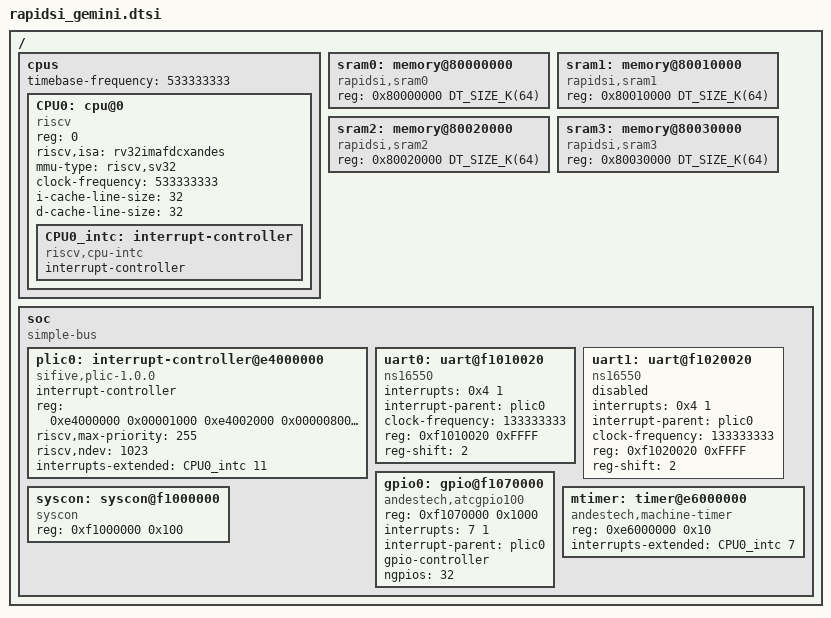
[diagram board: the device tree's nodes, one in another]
/*
 * Copyright (c) 2022 Rapid Silicon
 *
 * SPDX-License-Identifier: Apache-2.0
 */

/dts-v1/;

#include <zephyr/dt-bindings/gpio/gpio.h>
#include <mem.h>

/ {
	#address-cells = <1>;
	#size-cells = <1>;

	cpus {
		#address-cells = <1>;
		#size-cells = <0>;
		timebase-frequency = <533333333>;
		CPU0: cpu@0 {
			compatible = "riscv";
			device_type = "cpu";
			reg = <0>;
			status = "okay";
			riscv,isa = "rv32imafdcxandes";
			mmu-type = "riscv,sv32";
			clock-frequency = <533333333>;
			i-cache-line-size = <32>;
			d-cache-line-size = <32>;
			CPU0_intc: interrupt-controller {
				compatible = "riscv,cpu-intc";
				#address-cells = <0>;
				#interrupt-cells = <1>;
				interrupt-controller;
			};
		};
	};

	sram0: memory@80000000 {
		compatible = "rapidsi,sram0";
		device_type = "memory";
		reg = <0x80000000 DT_SIZE_K(64)>;
	};

	sram1: memory@80010000 {
		compatible = "rapidsi,sram1";
		device_type = "memory";
		reg = <0x80010000 DT_SIZE_K(64)>;
	};

	sram2: memory@80020000 {
		compatible = "rapidsi,sram2";
		device_type = "memory";
		reg = <0x80020000 DT_SIZE_K(64)>;
	};

	sram3: memory@80030000 {
		compatible = "rapidsi,sram3";
		device_type = "memory";
		reg = <0x80030000 DT_SIZE_K(64)>;
	};

	soc {
		#address-cells = <1>;
		#size-cells = <1>;
		compatible = "simple-bus";
		ranges;

		plic0: interrupt-controller@e4000000 {
			compatible = "sifive,plic-1.0.0";
			#address-cells = <1>;
			#interrupt-cells = <2>;
			interrupt-controller;
			reg = <	0xe4000000 0x00001000
				0xe4002000 0x00000800
				0xe4200000 0x00010000 >;
			reg-names = "prio", "irq_en", "reg";
			riscv,max-priority = <255>;
			riscv,ndev = <1023>;
			interrupts-extended = <&CPU0_intc 11>;
		};

		uart0: uart@f1010020 {
			interrupts = < 0x4 1 >;
			interrupt-parent = < &plic0 >;
			clock-frequency = < 133333333 >;
			reg = < 0xf1010020 0xFFFF >;
			compatible = "ns16550";
			reg-shift = < 2 >;
			status = "okay";
		};

		uart1: uart@f1020020 {
			interrupts = < 0x4 1 >;
			interrupt-parent = < &plic0 >;
			clock-frequency = < 133333333 >;
			reg = < 0xf1020020 0xFFFF >;
			compatible = "ns16550";
			reg-shift = < 2 >;
			status = "disabled";
		};

		gpio0: gpio@f1070000 {
			compatible = "andestech,atcgpio100";
			reg = <0xf1070000 0x1000>;
			interrupts = <7 1>;
			interrupt-parent = <&plic0>;
			gpio-controller;
			ngpios = <32>;
			#gpio-cells = <2>;
			status = "okay";
		};

		syscon: syscon@f1000000 {
			compatible = "syscon";
			reg = <0xf1000000 0x100>;
			status = "okay";
		};

		mtimer: timer@e6000000 {
			compatible = "andestech,machine-timer";
			reg = <0xe6000000 0x10>;
			interrupts-extended = <&CPU0_intc 7>;
			status = "okay";
		};
	};
};
